# STM32H573 register map
File version: 0.4
CPU: CM33 r0p0, little endian, MPU, FPU, 4 interrupt priority bits
Registers are 32-bit, read-write, reset 0x0 unless marked. A register's access mark holds for its fields unless they carry their own. Offsets are from the block's base; [hi:lo] are bit positions.

## PKA — Private key accelerator
Base 0x420C2000
Same registers: SEC_PKA 0x520C2000
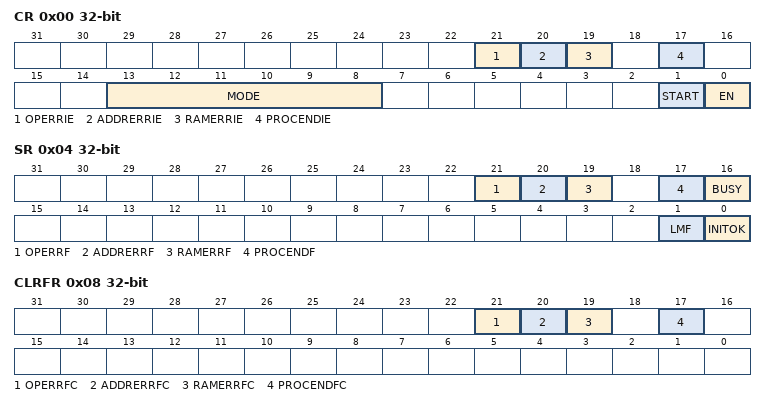
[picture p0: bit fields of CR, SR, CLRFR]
0x00 CR — PKA control register
  [21] OPERRIE — Operation error interrupt enable
  [20] ADDRERRIE — Address error interrupt enable
  [19] RAMERRIE — RAM error interrupt enable
  [17] PROCENDIE — End of operation interrupt enable
  [13:8] MODE — PKA operation code When an operation not listed here is written by the application with EN bit set, OPERRF bit is set in PKA_SR register, and the write to MODE bitfield is ignored. When PKA is configured in limited mode (LMF = 1 in PKA_SR), writing a MODE different from 0x26 with EN bit to 1 triggers OPERRF bit to be set and write to MODE bit is ignored.
  [1] START — start the operation Writing 1 to this bit starts the operation which is selected by MODE[5:0], using the operands and data already written to the PKA RAM. This bit is always read as 0. When an illegal operation is selected while START bit is set no operation is started, and OPERRF bit is set in PKA_SR. START is ignored if PKA is busy.
  [0] EN — PKA enable. When an illegal operation is selected while EN=1 OPERRF bit is set in PKA_SR. See PKA_CR.MODE bitfield for details. When EN=0 PKA RAM can still be accessed by the application.
0x04 SR ro — PKA status register
  [21] OPERRF — Operation error flag This bit is cleared using OPERRFC bit in PKA_CLRFR.
  [20] ADDRERRF — Address error flag This bit is cleared using ADDRERRFC bit in PKA_CLRFR.
  [19] RAMERRF — PKA RAM error flag This bit is cleared using RAMERRFC bit in PKA_CLRFR.
  [17] PROCENDF — PKA End of Operation flag
  [16] BUSY — PKA operation is in progress This bit is set to 1 whenever START bit in the PKA_CR is set. It is automatically cleared when the computation is complete, meaning that PKA RAM can be safely accessed and a new operation can be started. If PKA is started with a wrong opcode, it is busy for a couple of cycles, then it aborts automatically the operation and go back to ready (BUSY bit is set to 0).
  [1] LMF — Limited mode flag This bit is updated when EN bit in PKA_CR is set
  [0] INITOK — PKA initialization OK This bit is asserted when PKA initialization is complete. When RNG is not able to output proper random numbers INITOK stays at 0.
0x08 CLRFR wo — PKA clear flag register
  [21] OPERRFC — Clear operation error flag
  [20] ADDRERRFC — Clear address error flag
  [19] RAMERRFC — Clear PKA RAM error flag
  [17] PROCENDFC — Clear PKA End of Operation flag

## TIM6 — Basic timers
Base 0x40001000
Same registers: SEC_TIM6 0x50001000
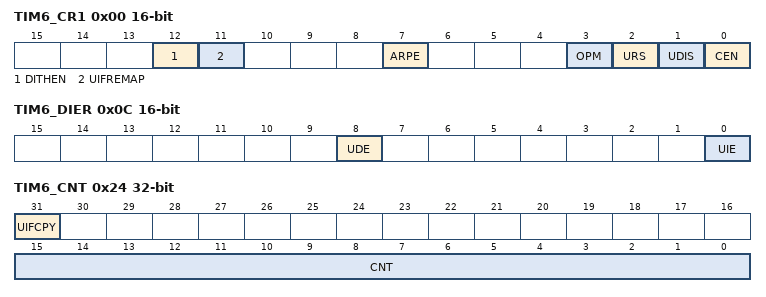
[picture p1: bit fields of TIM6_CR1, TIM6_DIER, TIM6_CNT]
0x00 TIM6_CR1 16-bit — TIM6 control register 1
  [12] DITHEN — Dithering enable Note: The DITHEN bit can only be modified when CEN bit is reset.
  [11] UIFREMAP — UIF status bit remapping
  [7] ARPE — Auto-reload preload enable
  [3] OPM — One-pulse mode
  [2] URS — Update request source This bit is set and cleared by software to select the UEV event sources. Counter overflow/underflow Setting the UG bit Update generation through the slave mode controller
  [1] UDIS — Update disable This bit is set and cleared by software to enable/disable UEV event generation. Counter overflow/underflow Setting the UG bit Update generation through the slave mode controller Buffered registers are then loaded with their preload values.
  [0] CEN — Counter enable CEN is cleared automatically in one-pulse mode, when an update event occurs.
0x04 TIM6_CR2 16-bit — TIM6 control register 2
  [6:4] MMS — Master mode selection These bits are used to select the information to be sent in master mode to slave timers for synchronization (TRGO). The combination is as follows: Note: The clock of the slave timer or he peripheral receiving the tim_trgo must be enabled prior to receive events from the master timer, and must not be changed on-the-fly while triggers are received from the master timer.
0x0C TIM6_DIER 16-bit — TIM6 DMA/Interrupt enable register
  [8] UDE — Update DMA request enable
  [0] UIE — Update interrupt enable
0x10 TIM6_SR 16-bit — TIM6 status register
  [0] UIF — Update interrupt flag This bit is set by hardware on an update event. It is cleared by software. On counter overflow if UDIS = 0 in the TIMx_CR1 register. When CNT is reinitialized by software using the UG bit in the TIMx_EGR register, if URS = 0 and UDIS = 0 in the TIMx_CR1 register.
0x14 TIM6_EGR 16-bit wo — TIM6 event generation register
  [0] UG — Update generation This bit can be set by software, it is automatically cleared by hardware.
0x24 TIM6_CNT access per field — TIM6 counter
  [31] UIFCPY ro — UIF copy This bit is a read-only copy of the UIF bit of the TIMx_ISR register. If the UIFREMAP bit in TIMx_CR1 is reset, bit 31 is reserved and read as 0.
  [15:0] CNT rw — Counter value Non-dithering mode (DITHEN = 0) The register holds the counter value. Dithering mode (DITHEN = 1) The register only holds the non-dithered part in CNT[15:0]. The fractional part is not available.
0x28 TIM6_PSC 16-bit — TIM6 prescaler
  [15:0] PSC — Prescaler value The counter clock frequency ftim_cnt_ck is equal to ftim_psc_ck / (PSC[15:0] + 1). PSC contains the value to be loaded into the active prescaler register at each update event. (including when the counter is cleared through UG bit of TIMx_EGR register.
0x2C TIM6_ARR reset 0xFFFF — TIM6 auto-reload register
  [19:0] ARR — Auto-reload value ARR is the value to be loaded into the actual auto-reload register. Refer to for more details about ARR update and behavior. The counter is blocked while the auto-reload value is null. Non-dithering mode (DITHEN = 0) The register holds the auto-reload value in ARR[15:0]. The ARR[19:16] bits are reserved. Dithering mode (DITHEN = 1) The register holds the integer part in ARR[19:4]. The ARR[3:0] bitfield contains the dithered part.

## TIM7 — Basic timers
Base 0x40001400
Same registers: SEC_TIM7 0x50001400
Registers as TIM6 (with TIM6 read as TIM7).
